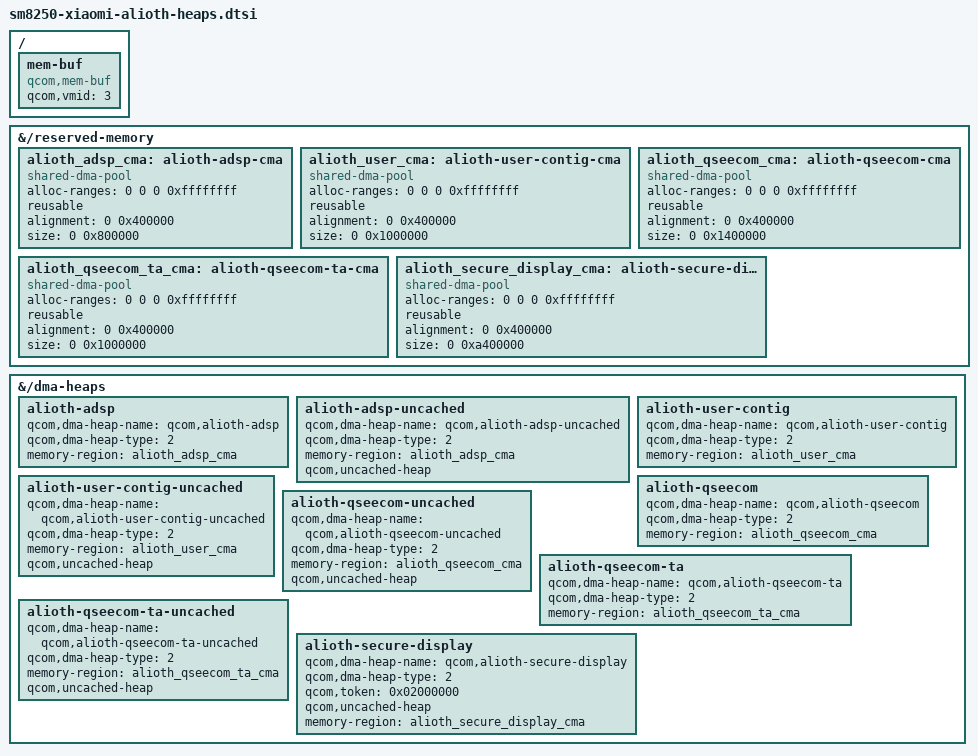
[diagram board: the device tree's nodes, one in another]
// SPDX-License-Identifier: GPL-2.0-only
/* Nonsecure donor CMA pools; no secure heap is substituted here. */
&{/reserved-memory} {
	alioth_adsp_cma: alioth-adsp-cma {
		compatible = "shared-dma-pool";
		alloc-ranges = <0 0 0 0xffffffff>;
		reusable;
		alignment = <0 0x400000>;
		size = <0 0x800000>;
	};
	alioth_user_cma: alioth-user-contig-cma {
		compatible = "shared-dma-pool";
		alloc-ranges = <0 0 0 0xffffffff>;
		reusable;
		alignment = <0 0x400000>;
		size = <0 0x1000000>;
	};
};

/* HEAP_TYPE_CMA = 2 in linux/qcom_dma_heap_dt_constants.h. */
&{/dma-heaps} {
	alioth-adsp {
		qcom,dma-heap-name = "qcom,alioth-adsp";
		qcom,dma-heap-type = <2>;
		memory-region = <&alioth_adsp_cma>;
	};
	alioth-adsp-uncached {
		qcom,dma-heap-name = "qcom,alioth-adsp-uncached";
		qcom,dma-heap-type = <2>;
		memory-region = <&alioth_adsp_cma>;
		qcom,uncached-heap;
	};
	alioth-user-contig {
		qcom,dma-heap-name = "qcom,alioth-user-contig";
		qcom,dma-heap-type = <2>;
		memory-region = <&alioth_user_cma>;
	};
	alioth-user-contig-uncached {
		qcom,dma-heap-name = "qcom,alioth-user-contig-uncached";
		qcom,dma-heap-type = <2>;
		memory-region = <&alioth_user_cma>;
		qcom,uncached-heap;
	};
};

/ {
	mem-buf {
		compatible = "qcom,mem-buf";
		/* VMID_HLOS in soc/qcom/secure_buffer.h. */
		qcom,vmid = <3>;
	};
};

&{/reserved-memory} {
	alioth_qseecom_cma: alioth-qseecom-cma {
		compatible = "shared-dma-pool";
		alloc-ranges = <0 0 0 0xffffffff>;
		reusable;
		alignment = <0 0x400000>;
		size = <0 0x1400000>;
	};
};

&{/dma-heaps} {
	alioth-qseecom {
		qcom,dma-heap-name = "qcom,alioth-qseecom";
		qcom,dma-heap-type = <2>;
		memory-region = <&alioth_qseecom_cma>;
	};
	alioth-qseecom-uncached {
		qcom,dma-heap-name = "qcom,alioth-qseecom-uncached";
		qcom,dma-heap-type = <2>;
		memory-region = <&alioth_qseecom_cma>;
		qcom,uncached-heap;
	};
};

&{/reserved-memory} {
	alioth_qseecom_ta_cma: alioth-qseecom-ta-cma {
		compatible = "shared-dma-pool";
		alloc-ranges = <0 0 0 0xffffffff>;
		reusable;
		alignment = <0 0x400000>;
		size = <0 0x1000000>;
	};
};

&{/dma-heaps} {
	alioth-qseecom-ta {
		qcom,dma-heap-name = "qcom,alioth-qseecom-ta";
		qcom,dma-heap-type = <2>;
		memory-region = <&alioth_qseecom_ta_cma>;
	};
	alioth-qseecom-ta-uncached {
		qcom,dma-heap-name = "qcom,alioth-qseecom-ta-uncached";
		qcom,dma-heap-type = <2>;
		memory-region = <&alioth_qseecom_ta_cma>;
		qcom,uncached-heap;
	};
};

/* Donor secure UI CMA pool: heap 10, 164 MiB, 4 MiB alignment. */
&{/reserved-memory} {
 alioth_secure_display_cma: alioth-secure-display-cma {
  compatible = "shared-dma-pool";
  alloc-ranges = <0 0 0 0xffffffff>;
  reusable;
  alignment = <0 0x400000>;
  size = <0 0xa400000>;
 };
};
&{/dma-heaps} {
 alioth-secure-display {
  qcom,dma-heap-name = "qcom,alioth-secure-display";
  qcom,dma-heap-type = <2>;
  qcom,token = <0x02000000>;
  qcom,uncached-heap;
  memory-region = <&alioth_secure_display_cma>;
 };
};
